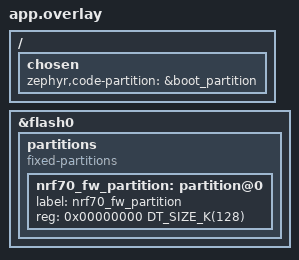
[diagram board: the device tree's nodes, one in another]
/ {
	chosen {
		zephyr,code-partition = &boot_partition;
	};
};

&flash0 {
    partitions {
        compatible = "fixed-partitions";
        #address-cells = <1>;
        #size-cells = <1>;
        nrf70_fw_partition: partition@0 {
            label = "nrf70_fw_partition";
            reg = <0x00000000 DT_SIZE_K(128)>;
        };
    };
};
